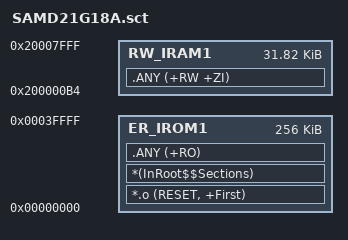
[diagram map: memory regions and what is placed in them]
;SAMD21G18A
;256KB FLASH (0x40000) @ 0x000000000
;2KB RAM (0x8000) @ 0x20000000


;SAMD21G18A: 256KB FLASH (0x40000) + 32KB RAM (0x8000)
LR_IROM1 0x00000000 0x40000  {    ; load region size_region
    ER_IROM1 0x00000000 0x40000  {  ; load address = execution address 
        *.o (RESET, +First)
        *(InRoot$$Sections)
        .ANY (+RO)
    }

    ; [RAM] Vector table dynamic copy: 45 vectors * 4 bytes = (0xB4) - alignment
    RW_IRAM1 (0x20000000+0xB4) (0x8000-0xB4)  {  ; RW data
        .ANY (+RW +ZI)
    }

}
